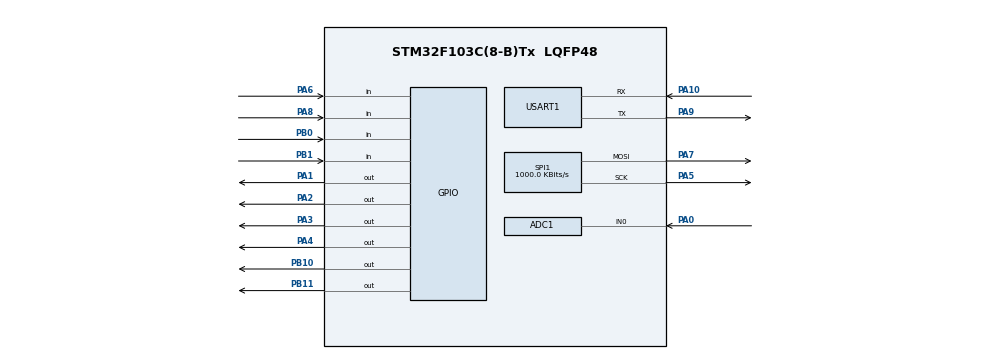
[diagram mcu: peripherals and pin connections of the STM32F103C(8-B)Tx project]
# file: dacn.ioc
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ADC1.Channel-0\#ChannelRegularConversion=ADC_CHANNEL_0
ADC1.NbrOfConversionFlag=1
ADC1.Rank-0\#ChannelRegularConversion=1
ADC1.SamplingTime-0\#ChannelRegularConversion=ADC_SAMPLETIME_1CYCLE_5
ADC1.master=1
Mcu.Family=STM32F1
Mcu.Name=STM32F103C(8-B)Tx
Mcu.Package=LQFP48
NVIC.ADC1_2_IRQn=true\:0\:0\:false\:false\:true\:true\:true\:true
NVIC.PriorityGroup=NVIC_PRIORITYGROUP_4
NVIC.SPI1_IRQn=true\:0\:0\:false\:false\:true\:true\:true\:true
NVIC.USART1_IRQn=true\:0\:0\:false\:false\:true\:true\:true\:true
PA0-WKUP.Signal=ADCx_IN0
PA1.Signal=GPIO_Output
PA10.Mode=Asynchronous
PA10.Signal=USART1_RX
PA2.Signal=GPIO_Output
PA3.Signal=GPIO_Output
PA4.Signal=GPIO_Output
PA5.Mode=TX_Only_Simplex_Unidirect_Master
PA5.Signal=SPI1_SCK
PA6.Signal=GPIO_Input
PA7.Mode=TX_Only_Simplex_Unidirect_Master
PA7.Signal=SPI1_MOSI
PA8.Signal=GPIO_Input
PA9.Mode=Asynchronous
PA9.Signal=USART1_TX
PB0.Signal=GPIO_Input
PB1.Signal=GPIO_Input
PB10.Signal=GPIO_Output
PB11.Signal=GPIO_Output
PD0-OSC_IN.Mode=HSE-External-Oscillator
PD0-OSC_IN.Signal=RCC_OSC_IN
PD1-OSC_OUT.Mode=HSE-External-Oscillator
PD1-OSC_OUT.Signal=RCC_OSC_OUT
ProjectManager.HeapSize=0x200
ProjectManager.StackSize=0x400
ProjectManager.TargetToolchain=MDK-ARM V5.32
RCC.APB1Freq_Value=8000000
RCC.APB2Freq_Value=8000000
SH.ADCx_IN0.0=ADC1_IN0,IN0
SPI1.BaudRatePrescaler=SPI_BAUDRATEPRESCALER_8
SPI1.CalculateBaudRate=1000.0 KBits/s
SPI1.Direction=SPI_DIRECTION_2LINES
SPI1.Mode=SPI_MODE_MASTER
SPI1.VirtualType=VM_MASTER
USART1.VirtualMode=VM_ASYNC
VP_SYS_VS_ND.Mode=No_Debug
board=custom

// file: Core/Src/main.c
/* USER CODE BEGIN Header */
/**
  * @file : main.c
  * @brief: Do ECG AD8232, hien thi Nokia 5110, chuyen doi che do & truyen UART
  *         (logic ung dung nam trong ecg_app.c va cac module con)
  */
/* USER CODE END Header */
#include "main.h"

/* USER CODE BEGIN Includes */
#include "ecg_app.h"
/* USER CODE END Includes */

ADC_HandleTypeDef hadc1;
SPI_HandleTypeDef hspi1;
UART_HandleTypeDef huart1;

void SystemClock_Config(void);
static void MX_GPIO_Init(void);
static void MX_ADC1_Init(void);
static void MX_USART1_UART_Init(void);
static void MX_SPI1_Init(void);

int main(void)
{
  HAL_Init();
  SystemClock_Config();

  MX_GPIO_Init();
  MX_ADC1_Init();
  MX_USART1_UART_Init();
  MX_SPI1_Init();

  /* USER CODE BEGIN 2 */
  ECG_Init();
  /* USER CODE END 2 */

  while (1)
  {
    /* USER CODE BEGIN 3 */
    ECG_Loop();
    /* USER CODE END 3 */
  }
}

void SystemClock_Config(void)
{
  RCC_OscInitTypeDef RCC_OscInitStruct = {0};
  RCC_ClkInitTypeDef RCC_ClkInitStruct = {0};
  RCC_PeriphCLKInitTypeDef PeriphClkInit = {0};

  RCC_OscInitStruct.OscillatorType = RCC_OSCILLATORTYPE_HSI;
  RCC_OscInitStruct.HSIState = RCC_HSI_ON;
  RCC_OscInitStruct.HSICalibrationValue = RCC_HSICALIBRATION_DEFAULT;
  RCC_OscInitStruct.PLL.PLLState = RCC_PLL_NONE;
  if (HAL_RCC_OscConfig(&RCC_OscInitStruct) != HAL_OK) Error_Handler();

  RCC_ClkInitStruct.ClockType = RCC_CLOCKTYPE_HCLK|RCC_CLOCKTYPE_SYSCLK
                              |RCC_CLOCKTYPE_PCLK1|RCC_CLOCKTYPE_PCLK2;
  RCC_ClkInitStruct.SYSCLKSource = RCC_SYSCLKSOURCE_HSI;
  RCC_ClkInitStruct.AHBCLKDivider = RCC_SYSCLK_DIV1;
  RCC_ClkInitStruct.APB1CLKDivider = RCC_HCLK_DIV1;
  RCC_ClkInitStruct.APB2CLKDivider = RCC_HCLK_DIV1;
  if (HAL_RCC_ClockConfig(&RCC_ClkInitStruct, FLASH_LATENCY_0) != HAL_OK) Error_Handler();

  PeriphClkInit.PeriphClockSelection = RCC_PERIPHCLK_ADC;
  PeriphClkInit.AdcClockSelection = RCC_ADCPCLK2_DIV2;
  if (HAL_RCCEx_PeriphCLKConfig(&PeriphClkInit) != HAL_OK) Error_Handler();
}

static void MX_ADC1_Init(void)
{
  ADC_ChannelConfTypeDef sConfig = {0};

  hadc1.Instance = ADC1;
  hadc1.Init.ScanConvMode = ADC_SCAN_DISABLE;
  hadc1.Init.ContinuousConvMode = DISABLE;
  hadc1.Init.DiscontinuousConvMode = DISABLE;
  hadc1.Init.ExternalTrigConv = ADC_SOFTWARE_START;
  hadc1.Init.DataAlign = ADC_DATAALIGN_RIGHT;
  hadc1.Init.NbrOfConversion = 1;
  if (HAL_ADC_Init(&hadc1) != HAL_OK) Error_Handler();

  sConfig.Channel = ADC_CHANNEL_0;
  sConfig.Rank = ADC_REGULAR_RANK_1;
  sConfig.SamplingTime = ADC_SAMPLETIME_1CYCLE_5;
  if (HAL_ADC_ConfigChannel(&hadc1, &sConfig) != HAL_OK) Error_Handler();
}

static void MX_SPI1_Init(void)
{
  hspi1.Instance = SPI1;
  hspi1.Init.Mode = SPI_MODE_MASTER;
  hspi1.Init.Direction = SPI_DIRECTION_2LINES;
  hspi1.Init.DataSize = SPI_DATASIZE_8BIT;
  hspi1.Init.CLKPolarity = SPI_POLARITY_LOW;
  hspi1.Init.CLKPhase = SPI_PHASE_1EDGE;
  hspi1.Init.NSS = SPI_NSS_SOFT;
  hspi1.Init.BaudRatePrescaler = SPI_BAUDRATEPRESCALER_8;
  hspi1.Init.FirstBit = SPI_FIRSTBIT_MSB;
  hspi1.Init.TIMode = SPI_TIMODE_DISABLE;
  hspi1.Init.CRCCalculation = SPI_CRCCALCULATION_DISABLE;
  hspi1.Init.CRCPolynomial = 10;
  if (HAL_SPI_Init(&hspi1) != HAL_OK) Error_Handler();
}

static void MX_USART1_UART_Init(void)
{
  huart1.Instance = USART1;
  huart1.Init.BaudRate = 115200;
  huart1.Init.WordLength = UART_WORDLENGTH_8B;
  huart1.Init.StopBits = UART_STOPBITS_1;
  huart1.Init.Parity = UART_PARITY_NONE;
  huart1.Init.Mode = UART_MODE_TX_RX;
  huart1.Init.HwFlowCtl = UART_HWCONTROL_NONE;
  huart1.Init.OverSampling = UART_OVERSAMPLING_16;
  if (HAL_UART_Init(&huart1) != HAL_OK) Error_Handler();
}

static void MX_GPIO_Init(void)
{
  GPIO_InitTypeDef GPIO_InitStruct = {0};

  __HAL_RCC_GPIOA_CLK_ENABLE();
  __HAL_RCC_GPIOB_CLK_ENABLE();

  HAL_GPIO_WritePin(GPIOA, GPIO_PIN_1|GPIO_PIN_2|GPIO_PIN_3|GPIO_PIN_4, GPIO_PIN_RESET);
  HAL_GPIO_WritePin(GPIOB, GPIO_PIN_10|GPIO_PIN_11, GPIO_PIN_RESET);

  /* PA1 BL, PA2 CS, PA3 DC, PA4 RST: output cho Nokia 5110 */
  GPIO_InitStruct.Pin = GPIO_PIN_1|GPIO_PIN_2|GPIO_PIN_3|GPIO_PIN_4;
  GPIO_InitStruct.Mode = GPIO_MODE_OUTPUT_PP;
  GPIO_InitStruct.Pull = GPIO_NOPULL;
  GPIO_InitStruct.Speed = GPIO_SPEED_FREQ_LOW;
  HAL_GPIO_Init(GPIOA, &GPIO_InitStruct);

  /* PA6 nut UP, PA8 nut DOWN */
  GPIO_InitStruct.Pin = GPIO_PIN_6|GPIO_PIN_8;
  GPIO_InitStruct.Mode = GPIO_MODE_INPUT;
  GPIO_InitStruct.Pull = GPIO_NOPULL;
  HAL_GPIO_Init(GPIOA, &GPIO_InitStruct);

  /* PB0 LO+, PB1 LO- */
  GPIO_InitStruct.Pin = GPIO_PIN_0|GPIO_PIN_1;
  GPIO_InitStruct.Mode = GPIO_MODE_INPUT;
  GPIO_InitStruct.Pull = GPIO_PULLDOWN;
  HAL_GPIO_Init(GPIOB, &GPIO_InitStruct);

  /* PB10 SDN, PB11 buzzer */
  GPIO_InitStruct.Pin = GPIO_PIN_10|GPIO_PIN_11;
  GPIO_InitStruct.Mode = GPIO_MODE_OUTPUT_PP;
  GPIO_InitStruct.Pull = GPIO_NOPULL;
  GPIO_InitStruct.Speed = GPIO_SPEED_FREQ_LOW;
  HAL_GPIO_Init(GPIOB, &GPIO_InitStruct);
}

void Error_Handler(void)
{
  __disable_irq();
  while (1) {}
}
